# f28p65x_epwm_xbar_regs register map
Vendor: Texas Instruments
Peripheral module from a debugger description file (folder C2000).
Address unit: 16 bits
Registers are 32-bit, read-write, no defined reset value unless marked. A register's access mark holds for its fields unless they carry their own. Offsets are as the file gives them; lines under a group give offsets from that group; [hi:lo] are bit positions; {n}, {i} and the like mark numbered series; 'fields as' and 'values as' point back to an identical list; <NAME> marks a mode.

## EPWM_XBAR_REGS — EPWM XBAR Registers
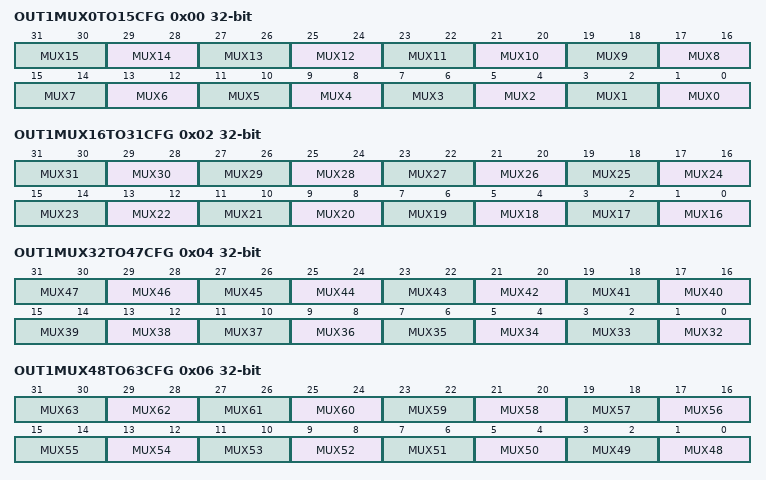
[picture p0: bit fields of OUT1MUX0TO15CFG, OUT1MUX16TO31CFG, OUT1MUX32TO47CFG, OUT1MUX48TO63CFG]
0x00 OUT1MUX0TO15CFG — ePWM XBAR Mux Configuration for Output1
  [2n+1:2n] MUX{n} (n=0..15) — MUX{n} Configuration for OUT1 of EPWM-XBAR
0x02 OUT1MUX16TO31CFG — ePWM XBAR Mux Configuration for Output1
  [2n-31:2n-32] MUX{n} (n=16..31) — MUX{n} Configuration for OUT1 of EPWM-XBAR
0x04 OUT1MUX32TO47CFG — ePWM XBAR Mux Configuration for Output1
  [2n-63:2n-64] MUX{n} (n=32..47) — MUX{n} Configuration for TRIP4 of EPWM-XBAR
0x06 OUT1MUX48TO63CFG — ePWM XBAR Mux Configuration for Output1
  [2n-95:2n-96] MUX{n} (n=48..63) — MUX{n} Configuration for OUT1 of EPWM-XBAR
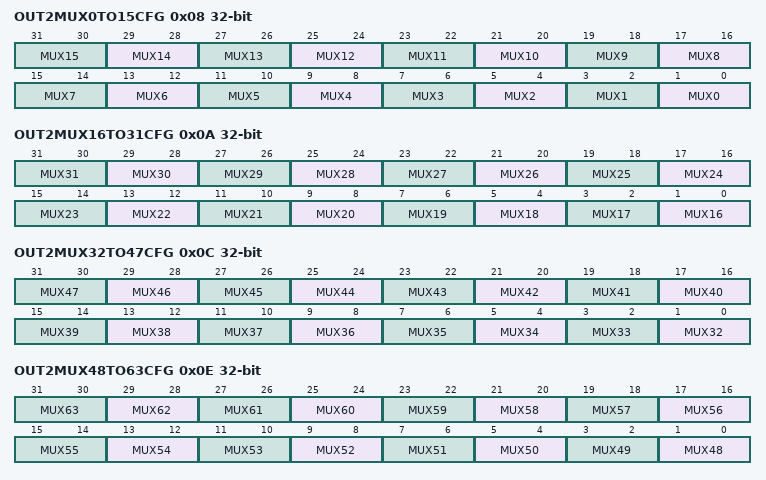
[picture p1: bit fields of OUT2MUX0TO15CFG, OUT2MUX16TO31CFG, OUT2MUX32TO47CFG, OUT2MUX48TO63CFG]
0x08 OUT2MUX0TO15CFG — ePWM XBAR Mux Configuration for Output2
  [2n+1:2n] MUX{n} (n=0..15) — MUX{n} Configuration for OUT2 of EPWM-XBAR
0x0A OUT2MUX16TO31CFG — ePWM XBAR Mux Configuration for Output2
  [2n-31:2n-32] MUX{n} (n=16..31) — MUX{n} Configuration for OUT2 of EPWM-XBAR
0x0C OUT2MUX32TO47CFG — ePWM XBAR Mux Configuration for Output2
  fields as OUT1MUX32TO47CFG
0x0E OUT2MUX48TO63CFG — ePWM XBAR Mux Configuration for Output2
  [2n-95:2n-96] MUX{n} (n=48..63) — MUX{n} Configuration for OUT2 of EPWM-XBAR
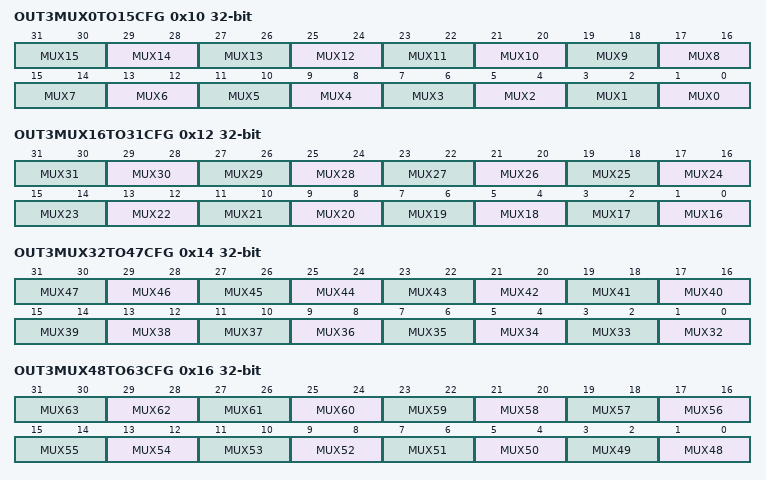
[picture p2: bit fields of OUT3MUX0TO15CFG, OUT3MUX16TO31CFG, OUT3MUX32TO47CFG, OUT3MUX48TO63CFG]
0x10 OUT3MUX0TO15CFG — ePWM XBAR Mux Configuration for Output3
  [2n+1:2n] MUX{n} (n=0..15) — MUX{n} Configuration for OUT3 of EPWM-XBAR
0x12 OUT3MUX16TO31CFG — ePWM XBAR Mux Configuration for Output3
  [2n-31:2n-32] MUX{n} (n=16..31) — MUX{n} Configuration for OUT3 of EPWM-XBAR
0x14 OUT3MUX32TO47CFG — ePWM XBAR Mux Configuration for Output3
  fields as OUT1MUX32TO47CFG
0x16 OUT3MUX48TO63CFG — ePWM XBAR Mux Configuration for Output3
  [2n-95:2n-96] MUX{n} (n=48..63) — MUX{n} Configuration for OUT3 of EPWM-XBAR
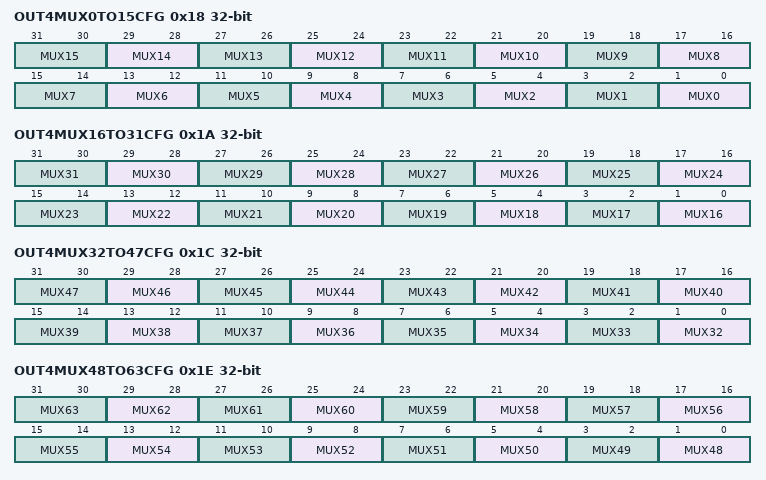
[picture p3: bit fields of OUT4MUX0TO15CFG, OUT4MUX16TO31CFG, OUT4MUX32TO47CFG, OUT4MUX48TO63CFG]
0x18 OUT4MUX0TO15CFG — ePWM XBAR Mux Configuration for Output4
  [2n+1:2n] MUX{n} (n=0..15) — MUX{n} Configuration for OUT4 of EPWM-XBAR
0x1A OUT4MUX16TO31CFG — ePWM XBAR Mux Configuration for Output4
  [2n-31:2n-32] MUX{n} (n=16..31) — MUX{n} Configuration for OUT4 of EPWM-XBAR
0x1C OUT4MUX32TO47CFG — ePWM XBAR Mux Configuration for Output4
  fields as OUT1MUX32TO47CFG
0x1E OUT4MUX48TO63CFG — ePWM XBAR Mux Configuration for Output4
  [2n-95:2n-96] MUX{n} (n=48..63) — MUX{n} Configuration for OUT4 of EPWM-XBAR
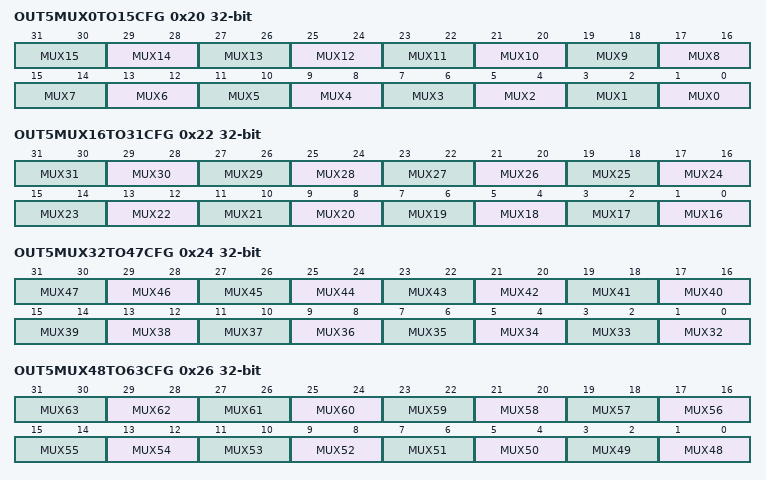
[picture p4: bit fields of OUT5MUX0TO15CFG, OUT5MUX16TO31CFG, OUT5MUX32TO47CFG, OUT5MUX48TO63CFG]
0x20 OUT5MUX0TO15CFG — ePWM XBAR Mux Configuration for Output5
  [2n+1:2n] MUX{n} (n=0..15) — MUX{n} Configuration for OUT5 of EPWM-XBAR
0x22 OUT5MUX16TO31CFG — ePWM XBAR Mux Configuration for Output5
  [2n-31:2n-32] MUX{n} (n=16..31) — MUX{n} Configuration for OUT5 of EPWM-XBAR
0x24 OUT5MUX32TO47CFG — ePWM XBAR Mux Configuration for Output5
  fields as OUT1MUX32TO47CFG
0x26 OUT5MUX48TO63CFG — ePWM XBAR Mux Configuration for Output5
  [2n-95:2n-96] MUX{n} (n=48..63) — MUX{n} Configuration for OUT5 of EPWM-XBAR
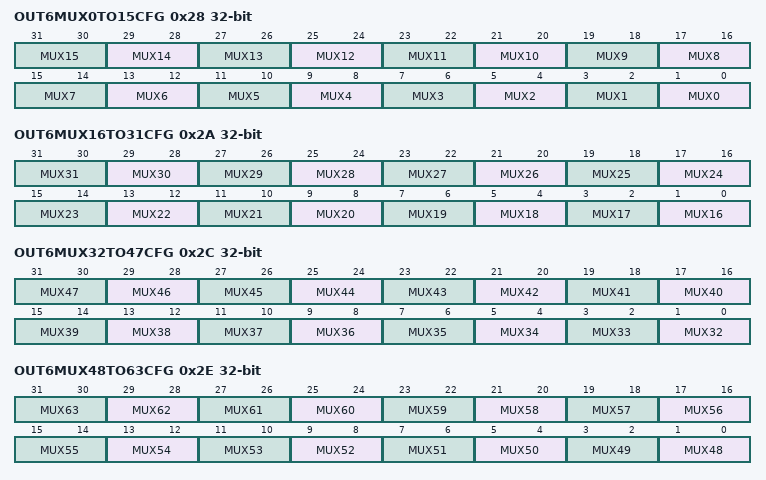
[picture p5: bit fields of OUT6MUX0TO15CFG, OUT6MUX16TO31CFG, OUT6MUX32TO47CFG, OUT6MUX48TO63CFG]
0x28 OUT6MUX0TO15CFG — ePWM XBAR Mux Configuration for Output6
  [2n+1:2n] MUX{n} (n=0..15) — MUX{n} Configuration for OUT6 of EPWM-XBAR
0x2A OUT6MUX16TO31CFG — ePWM XBAR Mux Configuration for Output6
  [2n-31:2n-32] MUX{n} (n=16..31) — MUX{n} Configuration for OUT6 of EPWM-XBAR
0x2C OUT6MUX32TO47CFG — ePWM XBAR Mux Configuration for Output6
  fields as OUT1MUX32TO47CFG
0x2E OUT6MUX48TO63CFG — ePWM XBAR Mux Configuration for Output6
  [2n-95:2n-96] MUX{n} (n=48..63) — MUX{n} Configuration for OUT6 of EPWM-XBAR
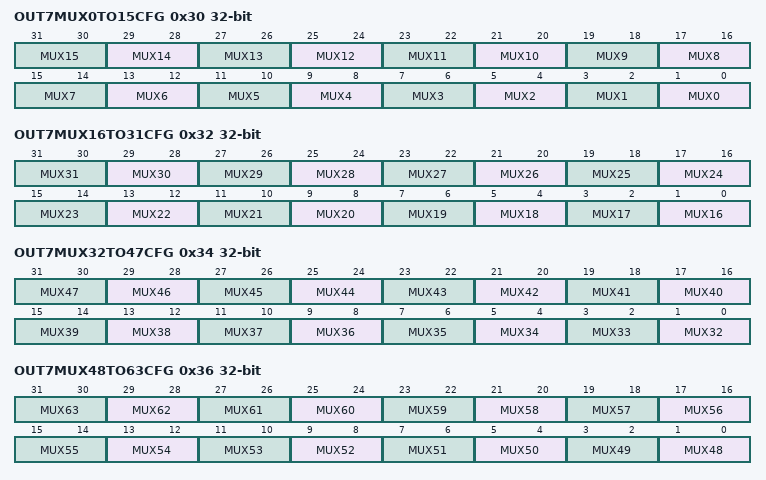
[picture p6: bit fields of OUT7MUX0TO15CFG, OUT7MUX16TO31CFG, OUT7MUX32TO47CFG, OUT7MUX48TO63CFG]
0x30 OUT7MUX0TO15CFG — ePWM XBAR Mux Configuration for Output7
  [2n+1:2n] MUX{n} (n=0..15) — MUX{n} Configuration for OUT7 of EPWM-XBAR
0x32 OUT7MUX16TO31CFG — ePWM XBAR Mux Configuration for Output7
  [2n-31:2n-32] MUX{n} (n=16..31) — MUX{n} Configuration for OUT7 of EPWM-XBAR
0x34 OUT7MUX32TO47CFG — ePWM XBAR Mux Configuration for Output7
  fields as OUT1MUX32TO47CFG
0x36 OUT7MUX48TO63CFG — ePWM XBAR Mux Configuration for Output7
  [2n-95:2n-96] MUX{n} (n=48..63) — MUX{n} Configuration for OUT7 of EPWM-XBAR
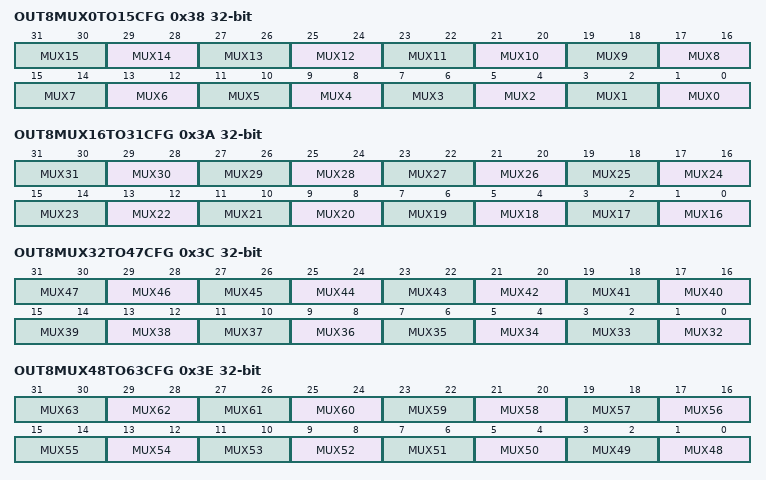
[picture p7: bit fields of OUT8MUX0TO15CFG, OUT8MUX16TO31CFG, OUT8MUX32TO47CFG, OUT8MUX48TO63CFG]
0x38 OUT8MUX0TO15CFG — ePWM XBAR Mux Configuration for Output8
  [2n+1:2n] MUX{n} (n=0..15) — MUX{n} Configuration for OUT8 of EPWM-XBAR
0x3A OUT8MUX16TO31CFG — ePWM XBAR Mux Configuration for Output8
  [2n-31:2n-32] MUX{n} (n=16..31) — MUX{n} Configuration for OUT8 of EPWM-XBAR
0x3C OUT8MUX32TO47CFG — ePWM XBAR Mux Configuration for Output8
  fields as OUT1MUX32TO47CFG
0x3E OUT8MUX48TO63CFG — ePWM XBAR Mux Configuration for Output8
  [2n-95:2n-96] MUX{n} (n=48..63) — MUX{n} Configuration for OUT8 of EPWM-XBAR
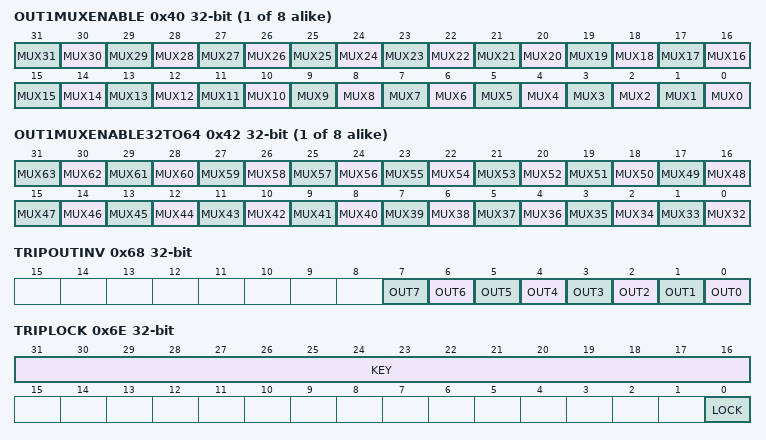
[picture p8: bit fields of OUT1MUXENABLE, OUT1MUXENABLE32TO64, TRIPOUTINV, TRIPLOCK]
{0x3C+4i} OUT{i}MUXENABLE (i=1..8) — ePWM XBAR Mux Enable for Output{i}
  [n] MUX{n} (n=0..31) — MUX{n} to drive OUT{i} of EPWM-XBAR
{0x3E+4i} OUT{i}MUXENABLE32TO64 (i=1..8) — ePWM XBAR Mux Enable for Output{i}
  [n-32] MUX{n} (n=32..63) — MUX{n} to drive OUT{i} of EPWM-XBAR
0x68 TRIPOUTINV — ePWM XBAR Output Inversion Register
  [n] OUT{n} (n=0..7) — Selects polarity for OUT{n} of EPWM-XBAR
0x6E TRIPLOCK — ePWM XBAR Configuration Lock register
  [31:16] KEY — Write protection KEY
  [0] LOCK — Locks the configuration for EPWM-XBAR
